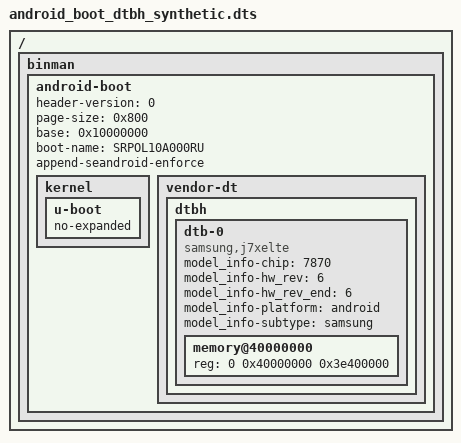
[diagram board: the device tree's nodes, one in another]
// SPDX-License-Identifier: GPL-2.0+

/dts-v1/;

/ {
	#address-cells = <1>;
	#size-cells = <1>;

	binman {
		android-boot {
			header-version = <0>;
			page-size = <0x800>;
			base = <0x10000000>;
			boot-name = "SRPOL10A000RU";
			append-seandroid-enforce;

			kernel {
				u-boot {
					no-expanded;
				};
			};

			vendor-dt {
				dtbh {
					dtb-0 {
						#address-cells = <2>;
						#size-cells = <1>;
						compatible = "samsung,j7xelte", "samsung,exynos7870";
						model_info-chip = <7870>;
						model_info-hw_rev = <6>;
						model_info-hw_rev_end = <6>;
						model_info-platform = "android";
						model_info-subtype = "samsung";

						memory@40000000 {
							device_type = "memory";
							reg = <0 0x40000000 0x3e400000>;
						};
					};
				};
			};
		};
	};
};
